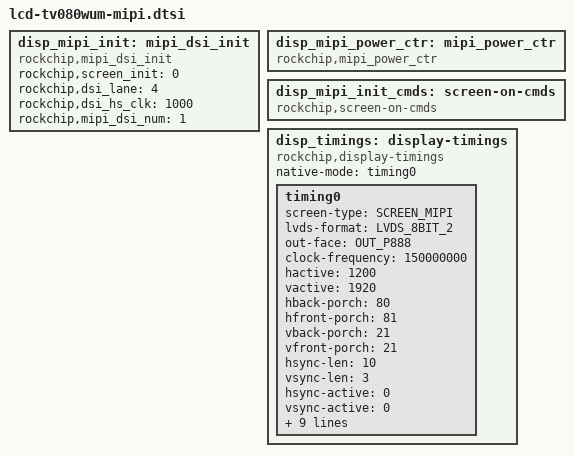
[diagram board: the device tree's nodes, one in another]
// SPDX-License-Identifier: (GPL-2.0+ OR MIT)
/*
 * Copyright (C) 2014 ROCKCHIP, Inc.
 * arch/arm/boot/dts/lcd-lq070m1sx01-mipi.dtsi
 * author: libing@rock-chips.com
 * create date: 2014-04-15
 * lcd model: ld089wu1
 * resolution: 1920 X 1200
 * mipi channel: single
 */

/* about mipi */
disp_mipi_init: mipi_dsi_init{
			compatible = "rockchip,mipi_dsi_init";
			rockchip,screen_init	= <0>;
			rockchip,dsi_lane		= <4>;
			rockchip,dsi_hs_clk		= <1000>;
			rockchip,mipi_dsi_num	= <1>;
};
disp_mipi_power_ctr: mipi_power_ctr {
			compatible = "rockchip,mipi_power_ctr";
			/*mipi_lcd_rst:mipi_lcd_rst{
					compatible = "rockchip,lcd_rst";
					rockchip,gpios = <&gpio2 GPIO_B7 GPIO_ACTIVE_LOW>;
					rockchip,delay = <100>;
			};
			mipi_lcd_en:mipi_lcd_en {
					compatible = "rockchip,lcd_en";
					rockchip,gpios = <&gpio0 GPIO_C1 GPIO_ACTIVE_HIGH>;
					rockchip,delay = <100>;
			};*/
};
disp_mipi_init_cmds: screen-on-cmds {
			compatible = "rockchip,screen-on-cmds";
			/*rockchip,cmd_debug = <1>;
			rockchip,on-cmds1 {
					compatible = "rockchip,on-cmds";
					rockchip,cmd_type = <HSDT>;
					rockchip,dsi_id = <2>;
					rockchip,cmd = <0xb0 0x02>;
					rockchip,cmd_delay = <0>;
			};
			*/
};


disp_timings: display-timings {
        native-mode = <&timing0>;
        compatible = "rockchip,display-timings";
        timing0: timing0 {
		screen-type = <SCREEN_MIPI>;
		lvds-format = <LVDS_8BIT_2>;
		out-face    = <OUT_P888>;
		clock-frequency = <150000000>;
		hactive = <1200>;
		vactive = <1920>;
		hback-porch = <80>;
		hfront-porch = <81>;
		vback-porch = <21>;
		vfront-porch = <21>;
		hsync-len = <10>;
		vsync-len = <3>;
		hsync-active = <0>;
		vsync-active = <0>;
		de-active = <0>;
		pixelclk-active = <0>;
		swap-rb = <0>;
		swap-rg = <0>;
		swap-gb = <0>;
		cabc-lut = <
			/*gamma = 2.2*/
			0x00000383 0x00000392 0x000003a2 0x000003b2 0x000003c2 0x000003d2 0x000003e2 0x000003f3
			0x00000403 0x00000414 0x00000425 0x00000436 0x00000447 0x00000458 0x0000046a 0x0000047b
			0x0000048d 0x0000049f 0x000004b1 0x000004c3 0x000004d5 0x000004e8 0x000004fa 0x0000050d
			0x00000520 0x00000533 0x00000546 0x0000055a 0x0000056d 0x00000581 0x00000595 0x000005a9
			0x000005bd 0x000005d1 0x000005e5 0x000005fa 0x0000060f 0x00000624 0x00000639 0x0000064e
			0x00000663 0x00000679 0x0000068e 0x000006a4 0x000006ba 0x000006d0 0x000006e6 0x000006fd
			0x00000713 0x0000072a 0x00000741 0x00000758 0x0000076f 0x00000786 0x0000079e 0x000007b6
			0x000007cd 0x000007e5 0x000007fd 0x00000816 0x0000082e 0x00000847 0x0000085f 0x00000878
			0x00000891 0x000008ab 0x000008c4 0x000008de 0x000008f7 0x00000911 0x0000092b 0x00000945
			0x00000960 0x0000097a 0x00000995 0x000009af 0x000009ca 0x000009e6 0x00000a01 0x00000a1c
			0x00000a38 0x00000a54 0x00000a6f 0x00000a8c 0x00000aa8 0x00000ac4 0x00000ae1 0x00000afd
			0x00000b1a 0x00000b37 0x00000b54 0x00000b72 0x00000b8f 0x00000bad 0x00000bcb 0x00000be9
			0x00000c07 0x00000c25 0x00000c44 0x00000c62 0x00000c81 0x00000ca0 0x00000cbf 0x00000cdf
			0x00000cfe 0x00000d1e 0x00000d3e 0x00000d5d 0x00000d7e 0x00000d9e 0x00000dbe 0x00000ddf
			0x00000e00 0x00000e21 0x00000e42 0x00000e63 0x00000e84 0x00000ea6 0x00000ec8 0x00000eea
			0x00000f0c 0x00000f2e 0x00000f50 0x00000f73 0x00000f96 0x00000fb9 0x00000fdc 0x00000fff
			0x00000000 0x00000000 0x00000000 0x00000000 0x00000000 0x00000000 0x00000000 0x00000000
			0x00000000 0x00000000 0x00000000 0x00000000 0x00000000 0x00000000 0x00000000 0x00000000
			0x00000000 0x00000000 0x00000000 0x00000000 0x00000000 0x00000000 0x00000000 0x00000000
			0x00000000 0x00000000 0x00000000 0x00000000 0x00000000 0x00000000 0x00000000 0x00000000
			0x00000000 0x00000000 0x00000000 0x00000000 0x00000000 0x00000000 0x00000000 0x00000000
			0x00000000 0x00000000 0x00000000 0x00000000 0x00000000 0x00000000 0x00000000 0x00000000
			0x00000000 0x00000000 0x00000000 0x00000000 0x00000000 0x00000000 0x00000000 0x00000000
			0x00000000 0x00000000 0x00000000 0x00000000 0x00000000 0x00000000 0x00000000 0x00000000
			0x00000000 0x00000000 0x00000000 0x00000000 0x00000000 0x00000000 0x00000000 0x00000000
			0x00000000 0x00000000 0x00000000 0x00000000 0x00000000 0x00000000 0x00000000 0x00000000
			0x00000000 0x00000000 0x00000000 0x00000000 0x00000000 0x00000000 0x00000000 0x00000000
			0x00000000 0x00000000 0x00000000 0x00000000 0x00000000 0x00000000 0x00000000 0x00000000
			0x00000000 0x00000000 0x00000000 0x00000000 0x00000000 0x00000000 0x00000000 0x00000000
			0x00000000 0x00000000 0x00000000 0x00000000 0x00000000 0x00000000 0x00000000 0x00000000
			0x00000000 0x00000000 0x00000000 0x00000000 0x00000000 0x00000000 0x00000000 0x00000000
			0x00000000 0x00000000 0x00000000 0x00000000 0x00000000 0x00000000 0x00000000 0x00000000>;
		cabc-gamma-base = <
			/*gamma = 2.2*/
			0x00010000 0x0000fdd0 0x0000fba8 0x0000f986 0x0000f76a 0x0000f556 0x0000f347 0x0000f140
			0x0000ef3e 0x0000ed43 0x0000eb4e 0x0000e95e 0x0000e775 0x0000e592 0x0000e3b4 0x0000e1dc
			0x0000e009 0x0000de3c 0x0000dc74 0x0000dab2 0x0000d8f4 0x0000d73c 0x0000d589 0x0000d3db
			0x0000d232 0x0000d08d 0x0000ceee 0x0000cd53 0x0000cbbc 0x0000ca2b 0x0000c89d 0x0000c714
			0x0000c590 0x0000c410 0x0000c294 0x0000c11c 0x0000bfa8 0x0000be39 0x0000bccd 0x0000bb65
			0x0000ba01 0x0000b8a1 0x0000b745 0x0000b5ed 0x0000b498 0x0000b347 0x0000b1f9 0x0000b0af
			0x0000af68 0x0000ae25 0x0000ace5 0x0000aba8 0x0000aa6f 0x0000a939 0x0000a806 0x0000a6d7
			0x0000a5aa 0x0000a480 0x0000a35a 0x0000a236 0x0000a116 0x00009ff8 0x00009edd 0x00009dc5
			0x00009cb0 0x00009b9e 0x00009a8e 0x00009981 0x00009877 0x0000976f 0x0000966a 0x00009567
			0x00009467 0x0000936a 0x0000926f 0x00009176 0x00009080 0x00008f8c 0x00008e9a 0x00008dab
			0x00008cbe 0x00008bd3 0x00008aea 0x00008a04 0x00008920 0x0000883e 0x0000875e 0x00008680
			0x000085a4 0x000084ca 0x000083f3 0x0000831d 0x00008249 0x00008177 0x000080a7 0x00007fd9
			0x00007f0d 0x00007e42 0x00007d7a 0x00007cb3 0x00007bee 0x00007b2b 0x00007a6a 0x000079aa
			0x000078ec 0x0000782f 0x00007775 0x000076bc 0x00007604 0x0000754f 0x0000749a 0x000073e8
			0x00007337 0x00007287 0x000071d9 0x0000712c 0x00007081 0x00006fd8 0x00006f30 0x00006e89
			0x00006de4 0x00006d40 0x00006c9d 0x00006bfc 0x00006b5c 0x00006abe 0x00006a21 0x00006985
			0x000068ea 0x00006851 0x000067b9 0x00006722 0x0000668d 0x000065f9 0x00006566 0x000064d4
			0x00006443 0x000063b4 0x00006325 0x00006298 0x0000620c 0x00006181 0x000060f8 0x0000606f
			0x00005fe7 0x00005f61 0x00005edb 0x00005e57 0x00005dd4 0x00005d51 0x00005cd0 0x00005c50
			0x00005bd1 0x00005b52 0x00005ad5 0x00005a59 0x000059de 0x00005963 0x000058ea 0x00005871
			0x000057fa 0x00005783 0x0000570d 0x00005699 0x00005625 0x000055b2 0x0000553f 0x000054ce
			0x0000545d 0x000053ee 0x0000537f 0x00005311 0x000052a4 0x00005238 0x000051cc 0x00005161
			0x000050f7 0x0000508e 0x00005026 0x00004fbe 0x00004f57 0x00004ef1 0x00004e8c 0x00004e27
			0x00004dc3 0x00004d60 0x00004cfe 0x00004c9c 0x00004c3b 0x00004bdb 0x00004b7b 0x00004b1c
			0x00004abe 0x00004a60 0x00004a03 0x000049a7 0x0000494b 0x000048f0 0x00004896 0x0000483c
			0x000047e3 0x0000478a 0x00004733 0x000046db 0x00004685 0x0000462f 0x000045d9 0x00004584
			0x00004530 0x000044dc 0x00004489 0x00004437 0x000043e5 0x00004393 0x00004342 0x000042f2
			0x000042a2 0x00004253 0x00004204 0x000041b6 0x00004169 0x0000411b 0x000040cf 0x00004083
			0x00004037 0x00003fec 0x00003fa1 0x00003f57 0x00003f0e 0x00003ec5 0x00003e7c 0x00003e34
			0x00003dec 0x00003da5 0x00003d5e 0x00003d18 0x00003cd2 0x00003c8c 0x00003c48 0x00003c03
			0x00003bbf 0x00003b7b 0x00003b38 0x00003af5 0x00003ab3 0x00003a71 0x00003a30 0x000039ef
			0x000039ae 0x0000396e 0x0000392e 0x000038ee 0x000038af 0x00003871 0x00003832 0x000037f5>;
			};
	};
